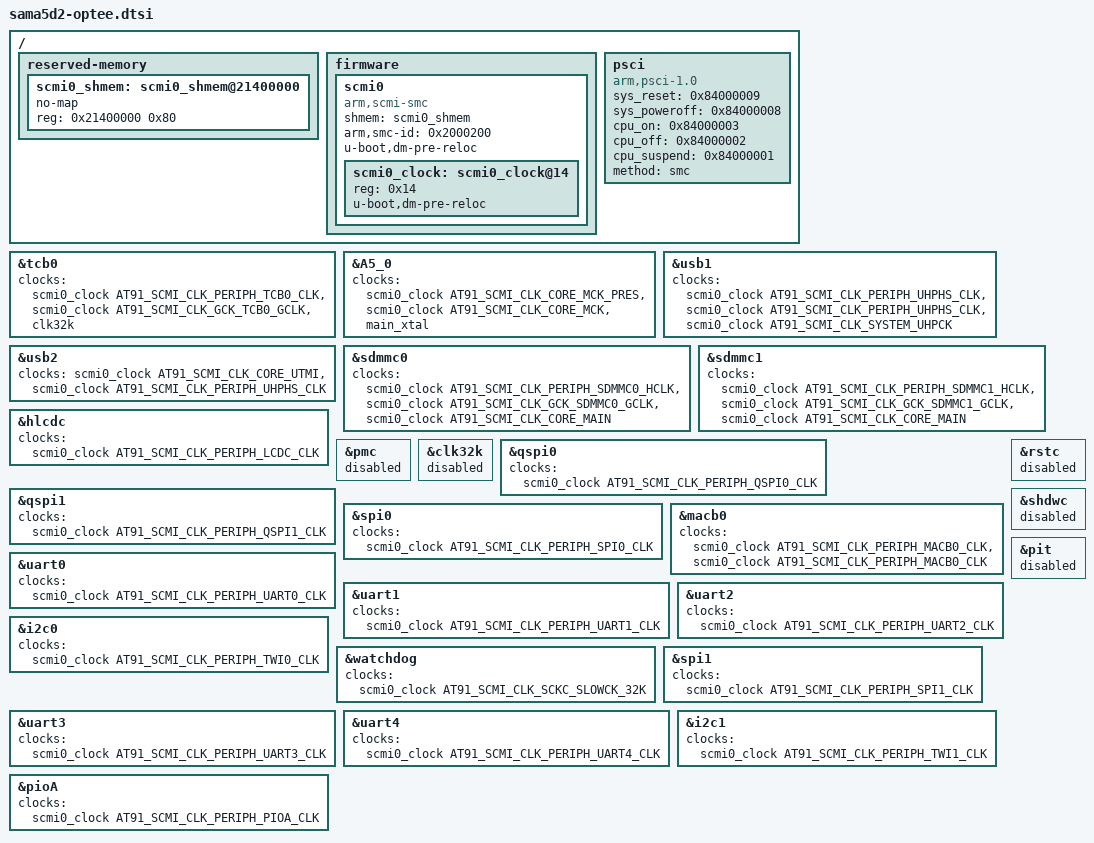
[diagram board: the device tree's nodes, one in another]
#include <dt-bindings/clk/at91.h>

/ {

	reserved-memory {
		ranges;
		#address-cells = <0x01>;
		#size-cells = <0x01>;

		scmi0_shmem: scmi0_shmem@21400000 {
			no-map;
			reg = <0x21400000 0x80>;
		};
	};

	firmware {
		scmi0 {
			compatible = "arm,scmi-smc";
			shmem = <&scmi0_shmem>;
			arm,smc-id = <0x2000200>;
			#address-cells = <0x01>;
			#size-cells = <0x00>;
			u-boot,dm-pre-reloc;

			scmi0_clock: scmi0_clock@14 {
				#clock-cells = <0x01>;
				reg = <0x14>;
				u-boot,dm-pre-reloc;
			};
		};
	};

	psci {
		sys_reset = <0x84000009>;
		sys_poweroff = <0x84000008>;
		cpu_on = <0x84000003>;
		cpu_off = <0x84000002>;
		cpu_suspend = <0x84000001>;
		method = "smc";
		compatible = "arm,psci-1.0", "arm,psci-0.2", "arm,psci";
	};
};

&tcb0 {
	clocks = <&scmi0_clock AT91_SCMI_CLK_PERIPH_TCB0_CLK>, <&scmi0_clock AT91_SCMI_CLK_GCK_TCB0_GCLK>, <&clk32k>;
};

&A5_0 {
	clocks = <&scmi0_clock AT91_SCMI_CLK_CORE_MCK_PRES>, <&scmi0_clock AT91_SCMI_CLK_CORE_MCK>, <&main_xtal>;
};

&usb1 {
	clocks = <&scmi0_clock AT91_SCMI_CLK_PERIPH_UHPHS_CLK>, <&scmi0_clock AT91_SCMI_CLK_PERIPH_UHPHS_CLK>, <&scmi0_clock AT91_SCMI_CLK_SYSTEM_UHPCK>;
};

&usb2 {
	clocks = <&scmi0_clock AT91_SCMI_CLK_CORE_UTMI>, <&scmi0_clock AT91_SCMI_CLK_PERIPH_UHPHS_CLK>;
};

&sdmmc0 {
	clocks = <&scmi0_clock AT91_SCMI_CLK_PERIPH_SDMMC0_HCLK>, <&scmi0_clock AT91_SCMI_CLK_GCK_SDMMC0_GCLK>, <&scmi0_clock AT91_SCMI_CLK_CORE_MAIN>;
};

&sdmmc1 {
	clocks = <&scmi0_clock AT91_SCMI_CLK_PERIPH_SDMMC1_HCLK>, <&scmi0_clock AT91_SCMI_CLK_GCK_SDMMC1_GCLK>, <&scmi0_clock AT91_SCMI_CLK_CORE_MAIN>;
};

&hlcdc {
	clocks = <&scmi0_clock AT91_SCMI_CLK_PERIPH_LCDC_CLK>;
};

&pmc {
	status = "disabled";
};

&clk32k {
	status = "disabled";
};

&qspi0 {
	clocks = <&scmi0_clock AT91_SCMI_CLK_PERIPH_QSPI0_CLK>;
};

&qspi1 {
	clocks = <&scmi0_clock AT91_SCMI_CLK_PERIPH_QSPI1_CLK>;
};

&spi0 {
	clocks = <&scmi0_clock AT91_SCMI_CLK_PERIPH_SPI0_CLK>;
};

&macb0 {
	clocks = <&scmi0_clock AT91_SCMI_CLK_PERIPH_MACB0_CLK>, <&scmi0_clock AT91_SCMI_CLK_PERIPH_MACB0_CLK>;
};

&uart0 {
	clocks = <&scmi0_clock AT91_SCMI_CLK_PERIPH_UART0_CLK>;
};

&uart1 {
	clocks = <&scmi0_clock AT91_SCMI_CLK_PERIPH_UART1_CLK>;
};

&uart2 {
	clocks = <&scmi0_clock AT91_SCMI_CLK_PERIPH_UART2_CLK>;
};

&i2c0 {
	clocks = <&scmi0_clock AT91_SCMI_CLK_PERIPH_TWI0_CLK>;
};

&rstc {
	status = "disabled";
};

&shdwc {
	status = "disabled";
};

&pit {
	status = "disabled";
};

&watchdog {
	clocks = <&scmi0_clock AT91_SCMI_CLK_SCKC_SLOWCK_32K>;
};

&spi1 {
	clocks = <&scmi0_clock AT91_SCMI_CLK_PERIPH_SPI1_CLK>;
};

&uart3 {
	clocks = <&scmi0_clock AT91_SCMI_CLK_PERIPH_UART3_CLK>;
};

&uart4 {
	clocks = <&scmi0_clock AT91_SCMI_CLK_PERIPH_UART4_CLK>;
};

&i2c1 {
	clocks = <&scmi0_clock AT91_SCMI_CLK_PERIPH_TWI1_CLK>;
};

&pioA {
	clocks = <&scmi0_clock AT91_SCMI_CLK_PERIPH_PIOA_CLK>;
};
